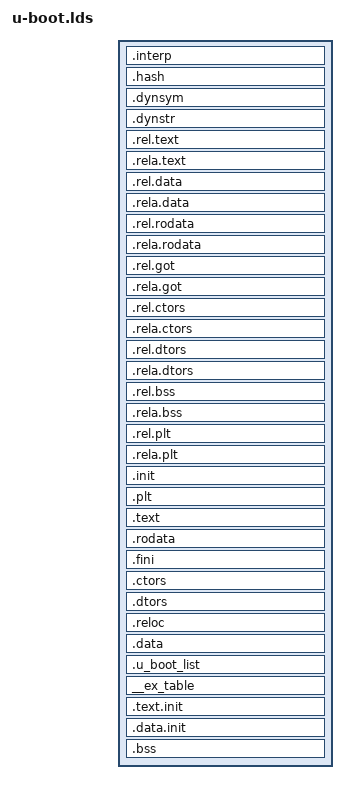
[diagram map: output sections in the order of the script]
/*
 * (C) Copyright 2000
 * Wolfgang Denk, DENX Software Engineering, wd@denx.de.
 *
 * SPDX-License-Identifier:	GPL-2.0+
 */

OUTPUT_ARCH(powerpc)
/* Do we need any of these for elf?
   __DYNAMIC = 0;    */
SECTIONS
{
  /* Read-only sections, merged into text segment: */
  . = + SIZEOF_HEADERS;
  .interp : { *(.interp) }
  .hash          : { *(.hash)		}
  .dynsym        : { *(.dynsym)		}
  .dynstr        : { *(.dynstr)		}
  .rel.text      : { *(.rel.text)		}
  .rela.text     : { *(.rela.text)	}
  .rel.data      : { *(.rel.data)		}
  .rela.data     : { *(.rela.data)	}
  .rel.rodata    : { *(.rel.rodata)	}
  .rela.rodata   : { *(.rela.rodata)	}
  .rel.got       : { *(.rel.got)		}
  .rela.got      : { *(.rela.got)		}
  .rel.ctors     : { *(.rel.ctors)	}
  .rela.ctors    : { *(.rela.ctors)	}
  .rel.dtors     : { *(.rel.dtors)	}
  .rela.dtors    : { *(.rela.dtors)	}
  .rel.bss       : { *(.rel.bss)		}
  .rela.bss      : { *(.rela.bss)		}
  .rel.plt       : { *(.rel.plt)		}
  .rela.plt      : { *(.rela.plt)		}
  .init          : { *(.init)	}
  .plt : { *(.plt) }
  .text      :
  {
    arch/powerpc/cpu/mpc8260/start.o	(.text)
    *(.text)
    *(.got1)
    /*. = env_offset; */
  }
  _etext = .;
  PROVIDE (etext = .);
  .rodata    :
  {
    *(.eh_frame)
    *(SORT_BY_ALIGNMENT(SORT_BY_NAME(.rodata*)))
  }
  .fini      : { *(.fini)    } =0
  .ctors     : { *(.ctors)   }
  .dtors     : { *(.dtors)   }

  /* Read-write section, merged into data segment: */
  . = (. + 0x0FFF) & 0xFFFFF000;
  _erotext = .;
  PROVIDE (erotext = .);
  .reloc   :
  {
    _GOT2_TABLE_ = .;
    KEEP(*(.got2))
    KEEP(*(.got))
    PROVIDE(_GLOBAL_OFFSET_TABLE_ = . + 4);
    _FIXUP_TABLE_ = .;
    KEEP(*(.fixup))
  }
  __got2_entries = ((_GLOBAL_OFFSET_TABLE_ - _GOT2_TABLE_) >> 2) - 1;
  __fixup_entries = (. - _FIXUP_TABLE_)>>2;

  .data    :
  {
    *(.data)
    *(.data1)
    *(.sdata)
    *(.sdata2)
    *(.dynamic)
    CONSTRUCTORS
  }
  _edata  =  .;
  PROVIDE (edata = .);

  . = .;

  . = ALIGN(4);
  .u_boot_list : {
	KEEP(*(SORT(.u_boot_list*)));
  }


  . = .;
  __start___ex_table = .;
  __ex_table : { *(__ex_table) }
  __stop___ex_table = .;

  . = ALIGN(4096);
  __init_begin = .;
  .text.init : { *(.text.init) }
  .data.init : { *(.data.init) }
  . = ALIGN(4096);
  __init_end = .;

  __bss_start = .;
  .bss (NOLOAD)       :
  {
   *(.sbss) *(.scommon)
   *(.dynbss)
   *(.bss)
   *(COMMON)
   . = ALIGN(4);
  }
  __bss_end = . ;
  PROVIDE (end = .);
}
